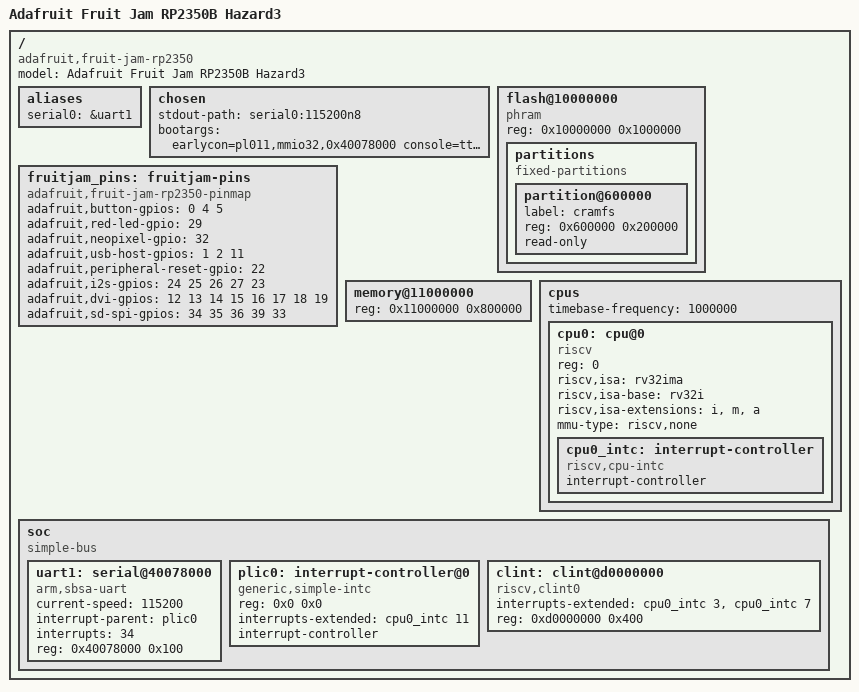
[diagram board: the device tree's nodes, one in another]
/dts-v1/;

/ {
	#address-cells = <1>;
	#size-cells = <1>;
	compatible = "adafruit,fruit-jam-rp2350", "raspberrypi,rp2350", "riscv-minimal-nommu";
	model = "Adafruit Fruit Jam RP2350B Hazard3";

	aliases {
		serial0 = &uart1;
	};

	chosen {
		stdout-path = "serial0:115200n8";
		bootargs = "earlycon=pl011,mmio32,0x40078000 console=ttyAMA0 root=mtd:cramfs rootfstype=cramfs ro";
	};

	flash@10000000 {
		compatible = "phram"; /* XIP flash mapped into physical address space */
		reg = <0x10000000 0x1000000>; /* 16 MiB QSPI flash */

		partitions {
			#address-cells = <1>;
			#size-cells = <1>;
			compatible = "fixed-partitions";

			partition@600000 {
				label = "cramfs";
				reg = <0x600000 0x200000>; /* rootfs.cramfs at 6 MiB */
				read-only;
			};
		};
	};

	fruitjam_pins: fruitjam-pins {
		compatible = "adafruit,fruit-jam-rp2350-pinmap";
		adafruit,button-gpios = <0 4 5>;
		adafruit,red-led-gpio = <29>;
		adafruit,neopixel-gpio = <32>;
		adafruit,usb-host-gpios = <1 2 11>;
		adafruit,peripheral-reset-gpio = <22>;
		adafruit,i2s-gpios = <24 25 26 27 23>;
		adafruit,dvi-gpios = <12 13 14 15 16 17 18 19>;
		adafruit,sd-spi-gpios = <34 35 36 39 33>;
	};

	memory@11000000 {
		device_type = "memory";
		reg = <0x11000000 0x800000>; /* 8 MiB external PSRAM */
	};

	cpus {
		#address-cells = <1>;
		#size-cells = <0>;
		timebase-frequency = <1000000>;

		cpu0: cpu@0 {
			reg = <0>;
			device_type = "cpu";
			compatible = "riscv";
			riscv,isa = "rv32ima";
			riscv,isa-base = "rv32i";
			riscv,isa-extensions = "i", "m", "a";
			mmu-type = "riscv,none";
			status = "okay";

			cpu0_intc: interrupt-controller {
				#interrupt-cells = <1>;
				#address-cells = <1>;
				interrupt-controller;
				compatible = "riscv,cpu-intc";
			};
		};
	};

	soc {
		#address-cells = <1>;
		#size-cells = <1>;
		compatible = "simple-bus";
		ranges;

		/* Fruit Jam's labeled TX/RX header pins are UART1 on GPIO8/GPIO9. */
		uart1: serial@40078000 {
			compatible = "arm,sbsa-uart";
			current-speed = <115200>;
			interrupt-parent = <&plic0>;
			interrupts = <34>;
			reg = <0x40078000 0x100>;
			status = "okay";
		};

		plic0: interrupt-controller@0 {
			reg = <0x0 0x0>;
			interrupts-extended = <&cpu0_intc 11>;
			interrupt-controller;
			compatible = "generic,simple-intc";
			#address-cells = <0x00>;
			#interrupt-cells = <0x01>;
		};

		clint: clint@d0000000 {
			interrupts-extended = <&cpu0_intc 3>,
					      <&cpu0_intc 7>;
			reg = <0xd0000000 0x400>;
			compatible = "riscv,clint0";
		};
	};
};
